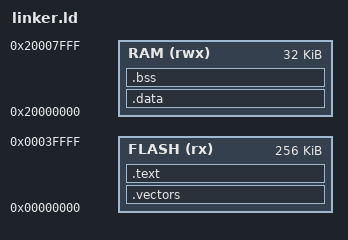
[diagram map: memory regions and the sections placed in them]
MEMORY
{
    FLASH (rx)  : ORIGIN = 0x00000000, LENGTH = 256K
    RAM   (rwx) : ORIGIN = 0x20000000, LENGTH = 32K
}

_estack = ORIGIN(RAM) + LENGTH(RAM);

SECTIONS
{
    .vectors :
    {
        . = ALIGN(256);
        KEEP(*(.vectors))
    } > FLASH

    .text :
    {
        . = ALIGN(4);
        *(.text*)
        *(.rodata*)
        . = ALIGN(4);
        _etext = .;
    } > FLASH

    .data : AT(_etext)
    {
        . = ALIGN(4);
        _sdata = .;
        *(.data*)
        . = ALIGN(4);
        _edata = .;
    } > RAM

    _sidata = LOADADDR(.data);

    .bss :
    {
        . = ALIGN(4);
        _sbss = .;
        *(.bss*)
        *(COMMON)
        . = ALIGN(4);
        _ebss = .;
    } > RAM

    . = ALIGN(8);
    _end = .;

    /DISCARD/ :
    {
        *(.comment)
        *(.note*)
        *(.eh_frame*)
    }
}
